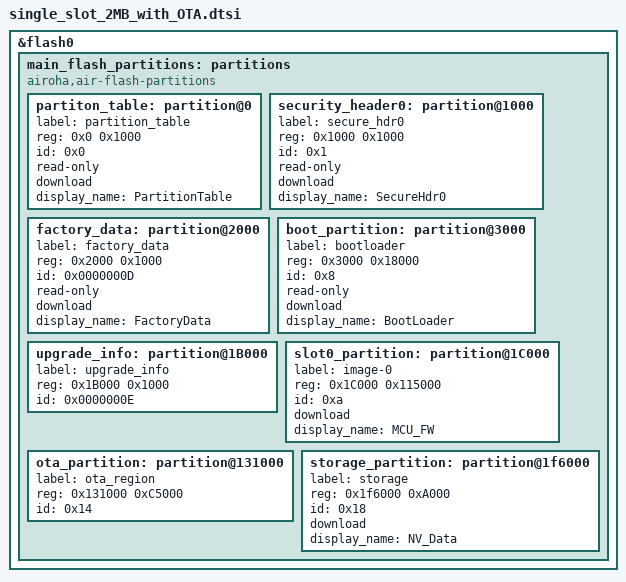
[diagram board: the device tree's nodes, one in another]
/* Copyright Statement:
 *
 * (C) 2025  Airoha Technology Corp. All rights reserved.
 *
 * This software/firmware and related documentation ("Airoha Software") are
 * protected under relevant copyright laws. The information contained herein
 * is confidential and proprietary to Airoha Technology Corp. ("Airoha") and/or its licensors.
 * Without the prior written permission of Airoha and/or its licensors,
 * any reproduction, modification, use or disclosure of Airoha Software,
 * and information contained herein, in whole or in part, shall be strictly prohibited.
 * You may only use, reproduce, modify, or distribute (as applicable) Airoha Software
 * if you have agreed to and been bound by the applicable license agreement with
 * Airoha ("License Agreement") and been granted explicit permission to do so within
 * the License Agreement ("Permitted User").  If you are not a Permitted User,
 * please cease any access or use of Airoha Software immediately.
 * BY OPENING THIS FILE, RECEIVER HEREBY UNEQUIVOCALLY ACKNOWLEDGES AND AGREES
 * THAT THE SOFTWARE/FIRMWARE AND ITS DOCUMENTATIONS ("AIROHA SOFTWARE")
 * RECEIVED FROM AIROHA AND/OR ITS REPRESENTATIVES ARE PROVIDED
 * TO RECEIVER ON AN "AS-IS" BASIS ONLY. AIROHA EXPRESSLY DISCLAIMS ANY AND ALL
 * WARRANTIES, EXPRESS OR IMPLIED, INCLUDING BUT NOT LIMITED TO THE IMPLIED WARRANTIES OF
 * MERCHANTABILITY, FITNESS FOR A PARTICULAR PURPOSE OR NONINFRINGEMENT.
 * NEITHER DOES AIROHA PROVIDE ANY WARRANTY WHATSOEVER WITH RESPECT TO THE
 * SOFTWARE OF ANY THIRD PARTY WHICH MAY BE USED BY, INCORPORATED IN, OR
 * SUPPLIED WITH AIROHA SOFTWARE, AND RECEIVER AGREES TO LOOK ONLY TO SUCH
 * THIRD PARTY FOR ANY WARRANTY CLAIM RELATING THERETO. RECEIVER EXPRESSLY ACKNOWLEDGES
 * THAT IT IS RECEIVER'S SOLE RESPONSIBILITY TO OBTAIN FROM ANY THIRD PARTY ALL PROPER LICENSES
 * CONTAINED IN AIROHA SOFTWARE. AIROHA SHALL ALSO NOT BE RESPONSIBLE FOR ANY AIROHA
 * SOFTWARE RELEASES MADE TO RECEIVER'S SPECIFICATION OR TO CONFORM TO A PARTICULAR
 * STANDARD OR OPEN FORUM. RECEIVER'S SOLE AND EXCLUSIVE REMEDY AND AIROHA'S ENTIRE AND
 * CUMULATIVE LIABILITY WITH RESPECT TO AIROHA SOFTWARE RELEASED HEREUNDER WILL BE,
 * AT AIROHA'S OPTION, TO REVISE OR REPLACE AIROHA SOFTWARE AT ISSUE,
 * OR REFUND ANY SOFTWARE LICENSE FEES OR SERVICE CHARGE PAID BY RECEIVER TO
 * AIROHA FOR SUCH AIROHA SOFTWARE AT ISSUE.
 */


/delete-node/ &main_flash_partitions;

&flash0 {
    main_flash_partitions: partitions {
        compatible = "airoha,air-flash-partitions", "fixed-partitions";
        #address-cells = < 0x1 >;
        #size-cells = < 0x1 >;
        partiton_table: partition@0 {
            label = "partition_table";
            reg = < 0x0 0x1000 >;
            id = < 0x0 >;
            read-only;
            download;
            display_name = "PartitionTable";
        };
        security_header0: partition@1000 {
            label = "secure_hdr0";
            reg = < 0x1000 0x1000 >;
            id = < 0x1 >;
            read-only;
            download;
            display_name = "SecureHdr0";
        };
        factory_data: partition@2000 {
            label = "factory_data";
            /* offset of flash device, partition size */
            reg = <0x2000 0x1000>;
            id = <0x0000000D>;
            read-only;
            download;
            display_name = "FactoryData";
        };
        boot_partition: partition@3000 {
            label = "bootloader";
            reg = < 0x3000 0x18000 >;
            id = < 0x8 >;
            read-only;
            download;
            display_name = "BootLoader";
        };
        upgrade_info: partition@1B000 {
            label = "upgrade_info";
            /* offset of flash device, partition size */
            reg = <0x1B000 0x1000>;
            id = <0x0000000E>;
        };
        slot0_partition: partition@1C000 {
            label = "image-0";
            reg = < 0x1C000 0x115000 >;
            id = < 0xa >;
            download;
            display_name = "MCU_FW";
        };
        ota_partition: partition@131000 {
            label = "ota_region";
            reg = < 0x131000 0xC5000 >;
            id = < 0x14 >;
        };
        storage_partition: partition@1f6000 {
            label = "storage";
            reg = < 0x1f6000 0xA000 >;
            id = < 0x18 >;
            download;
            display_name = "NV_Data";
        };
    };
};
